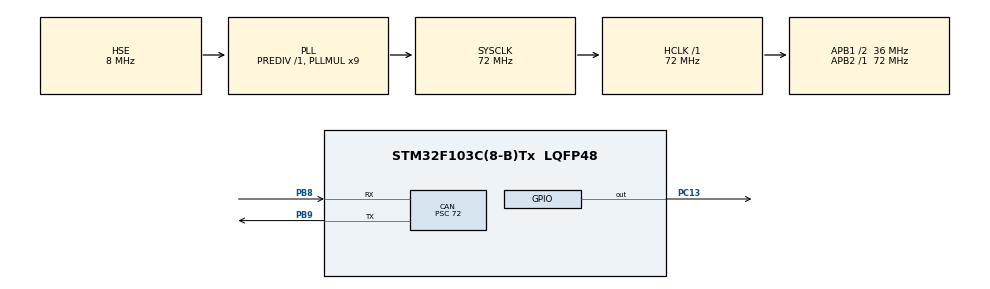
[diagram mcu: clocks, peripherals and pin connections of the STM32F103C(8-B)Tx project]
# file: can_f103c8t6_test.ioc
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CAN.ABOM=ENABLE
CAN.BS1=CAN_BS1_2TQ
CAN.CalculateBaudRate=125000
CAN.CalculateTimeBit=8000
CAN.CalculateTimeQuantum=2000.0
CAN.NART=ENABLE
CAN.Prescaler=72
Mcu.Family=STM32F1
Mcu.Name=STM32F103C(8-B)Tx
Mcu.Package=LQFP48
NVIC.CAN1_RX1_IRQn=true\:0\:0\:false\:false\:true\:true\:true\:true
NVIC.PriorityGroup=NVIC_PRIORITYGROUP_4
NVIC.TIM3_IRQn=true\:0\:0\:false\:false\:true\:true\:true\:true
PA13.Mode=Serial_Wire
PA13.Signal=SYS_JTMS-SWDIO
PA14.Mode=Serial_Wire
PA14.Signal=SYS_JTCK-SWCLK
PB8.Mode=CAN_Activate
PB8.Signal=CAN_RX
PB9.Mode=CAN_Activate
PB9.Signal=CAN_TX
PC13-TAMPER-RTC.Signal=GPIO_Output
PD0-OSC_IN.Mode=HSE-External-Oscillator
PD0-OSC_IN.Signal=RCC_OSC_IN
PD1-OSC_OUT.Mode=HSE-External-Oscillator
PD1-OSC_OUT.Signal=RCC_OSC_OUT
ProjectManager.HeapSize=0x200
ProjectManager.StackSize=0x400
ProjectManager.TargetToolchain=STM32CubeIDE
RCC.AHBFreq_Value=72000000
RCC.APB1CLKDivider=RCC_HCLK_DIV2
RCC.APB1Freq_Value=36000000
RCC.APB1TimFreq_Value=72000000
RCC.APB2Freq_Value=72000000
RCC.APB2TimFreq_Value=72000000
RCC.HCLKFreq_Value=72000000
RCC.PLLMUL=RCC_PLL_MUL9
RCC.PLLSourceVirtual=RCC_PLLSOURCE_HSE
RCC.SYSCLKFreq_VALUE=72000000
RCC.SYSCLKSource=RCC_SYSCLKSOURCE_PLLCLK
RCC.USBFreq_Value=72000000
TIM3.Period=1000-1
TIM3.Prescaler=72-1
VP_TIM3_VS_ClockSourceINT.Mode=Internal
board=custom

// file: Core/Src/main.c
/* USER CODE BEGIN Header */
/**
  ******************************************************************************
  * @file           : main.c
  * @brief          : Main program body
  ******************************************************************************
  * @attention
  *
  * Copyright (c) 2026 STMicroelectronics.
  * All rights reserved.
  *
  * This software is licensed under terms that can be found in the LICENSE file
  * in the root directory of this software component.
  * If no LICENSE file comes with this software, it is provided AS-IS.
  *
  ******************************************************************************
  */
/* USER CODE END Header */
#include "main.h"

/* USER CODE BEGIN Includes */

//--- Reference : https://www.youtube.com/watch?v=xGF5onNLZJs

//////////////////////////////////////////////////////////////////////
// PICK ONE OPTION (UNCOMMENT)
//////////////////////////////////////////////////////////////////////
//#define CAN_RX
#define CAN_TX

/* USER CODE END Includes */

CAN_HandleTypeDef hcan;

TIM_HandleTypeDef htim3;

void SystemClock_Config(void);
static void MX_GPIO_Init(void);
static void MX_CAN_Init(void);
static void MX_TIM3_Init(void);

/* USER CODE BEGIN 0 */
#ifdef CAN_TX
uint16_t readValue;
CAN_TxHeaderTypeDef TxHeader;
uint32_t TxMailbox;
uint8_t TxData[8]="HELLO---";
uint16_t txCNT = 0;
#endif

#ifdef CAN_RX
CAN_FilterTypeDef sFilterConfig;
CAN_RxHeaderTypeDef RxHeader;
uint8_t RxData[8];
uint8_t delayLED;
uint16_t delayCNT = 0;
uint8_t led_state = 0;

void HAL_CAN_RxFifo1MsgPendingCallback(CAN_HandleTypeDef *hcan)
{
	HAL_CAN_GetRxMessage(hcan, CAN_RX_FIFO1, &RxHeader, RxData);
	delayLED = RxData[7];
}
#endif

void HAL_TIM_PeriodElapsedCallback(TIM_HandleTypeDef *htim)
{
	if(htim == &htim3)
	{

#ifdef CAN_TX
		if(txCNT >= 99)
		{
			TxData[6] += 1;
			TxData[7] = TxData[6] + 1;
			txCNT = 0;
		}
		else
		{
			txCNT++;
		}

		if(HAL_CAN_GetTxMailboxesFreeLevel(&hcan) > 0)
		{
			HAL_CAN_AddTxMessage(&hcan, &TxHeader, TxData, &TxMailbox);
		}
#endif

#ifdef CAN_RX
		if(delayCNT >= delayLED)
		{
			led_state = !(led_state);
			HAL_GPIO_WritePin(GPIOC, GPIO_PIN_13, led_state);
			delayCNT = 0;
		}
		else
		{
			delayCNT++;
		}
#endif
	}
}

/* USER CODE END 0 */

int main(void)
{

  /* MCU Configuration--------------------------------------------------------*/

  /* Reset of all peripherals, Initializes the Flash interface and the Systick. */
  HAL_Init();

  /* Configure the system clock */
  SystemClock_Config();

  /* Initialize all configured peripherals */
  MX_GPIO_Init();
  MX_CAN_Init();
  MX_TIM3_Init();
  /* USER CODE BEGIN 2 */
#ifdef CAN_TX
  HAL_CAN_Start(&hcan);
  TxHeader.DLC = 8;  // data length
  TxHeader.IDE = CAN_ID_STD;
  TxHeader.RTR = CAN_RTR_DATA;
  TxHeader.StdId = 0x6A5;  // ID can be between Hex1 and Hex7FF (1-2047 decimal)
#endif

#ifdef CAN_RX
  HAL_CAN_Start(&hcan);
  // Configure the filter
  sFilterConfig.FilterActivation = CAN_FILTER_ENABLE;
  sFilterConfig.FilterFIFOAssignment = CAN_FILTER_FIFO1;
  sFilterConfig.FilterMode = CAN_FILTERMODE_IDMASK;
  sFilterConfig.FilterIdHigh = 0x6A5<<5;
  sFilterConfig.FilterIdLow = 0;
  sFilterConfig.FilterMaskIdHigh = 0x7FF<<5; // SET 0 to unfilter
  sFilterConfig.FilterMaskIdLow = 0;
  sFilterConfig.FilterScale = CAN_FILTERSCALE_32BIT;
  HAL_CAN_ConfigFilter(&hcan, &sFilterConfig);
  // Activate the notification
  HAL_CAN_ActivateNotification(&hcan, CAN_IT_RX_FIFO1_MSG_PENDING);
#endif

  HAL_TIM_Base_Start_IT(&htim3);

  /* USER CODE END 2 */

  /* Infinite loop */
  while (1)
  {

  }
}

void SystemClock_Config(void)
{
  RCC_OscInitTypeDef RCC_OscInitStruct = {0};
  RCC_ClkInitTypeDef RCC_ClkInitStruct = {0};

  /** Initializes the RCC Oscillators according to the specified parameters
  * in the RCC_OscInitTypeDef structure.
  */
  RCC_OscInitStruct.OscillatorType = RCC_OSCILLATORTYPE_HSE;
  RCC_OscInitStruct.HSEState = RCC_HSE_ON;
  RCC_OscInitStruct.HSEPredivValue = RCC_HSE_PREDIV_DIV1;
  RCC_OscInitStruct.HSIState = RCC_HSI_ON;
  RCC_OscInitStruct.PLL.PLLState = RCC_PLL_ON;
  RCC_OscInitStruct.PLL.PLLSource = RCC_PLLSOURCE_HSE;
  RCC_OscInitStruct.PLL.PLLMUL = RCC_PLL_MUL9;
  if (HAL_RCC_OscConfig(&RCC_OscInitStruct) != HAL_OK)
  {
    Error_Handler();
  }

  /** Initializes the CPU, AHB and APB buses clocks
  */
  RCC_ClkInitStruct.ClockType = RCC_CLOCKTYPE_HCLK|RCC_CLOCKTYPE_SYSCLK
                              |RCC_CLOCKTYPE_PCLK1|RCC_CLOCKTYPE_PCLK2;
  RCC_ClkInitStruct.SYSCLKSource = RCC_SYSCLKSOURCE_PLLCLK;
  RCC_ClkInitStruct.AHBCLKDivider = RCC_SYSCLK_DIV1;
  RCC_ClkInitStruct.APB1CLKDivider = RCC_HCLK_DIV2;
  RCC_ClkInitStruct.APB2CLKDivider = RCC_HCLK_DIV1;

  if (HAL_RCC_ClockConfig(&RCC_ClkInitStruct, FLASH_LATENCY_2) != HAL_OK)
  {
    Error_Handler();
  }
}

static void MX_CAN_Init(void)
{

  hcan.Instance = CAN1;
  hcan.Init.Prescaler = 72;
  hcan.Init.Mode = CAN_MODE_NORMAL;
  hcan.Init.SyncJumpWidth = CAN_SJW_1TQ;
  hcan.Init.TimeSeg1 = CAN_BS1_2TQ;
  hcan.Init.TimeSeg2 = CAN_BS2_1TQ;
  hcan.Init.TimeTriggeredMode = DISABLE;
  hcan.Init.AutoBusOff = ENABLE;
  hcan.Init.AutoWakeUp = DISABLE;
  hcan.Init.AutoRetransmission = ENABLE;
  hcan.Init.ReceiveFifoLocked = DISABLE;
  hcan.Init.TransmitFifoPriority = DISABLE;
  if (HAL_CAN_Init(&hcan) != HAL_OK)
  {
    Error_Handler();
  }

}

static void MX_TIM3_Init(void)
{

  TIM_ClockConfigTypeDef sClockSourceConfig = {0};
  TIM_MasterConfigTypeDef sMasterConfig = {0};

  htim3.Instance = TIM3;
  htim3.Init.Prescaler = 72-1;
  htim3.Init.CounterMode = TIM_COUNTERMODE_UP;
  htim3.Init.Period = 1000-1;
  htim3.Init.ClockDivision = TIM_CLOCKDIVISION_DIV1;
  htim3.Init.AutoReloadPreload = TIM_AUTORELOAD_PRELOAD_DISABLE;
  if (HAL_TIM_Base_Init(&htim3) != HAL_OK)
  {
    Error_Handler();
  }
  sClockSourceConfig.ClockSource = TIM_CLOCKSOURCE_INTERNAL;
  if (HAL_TIM_ConfigClockSource(&htim3, &sClockSourceConfig) != HAL_OK)
  {
    Error_Handler();
  }
  sMasterConfig.MasterOutputTrigger = TIM_TRGO_RESET;
  sMasterConfig.MasterSlaveMode = TIM_MASTERSLAVEMODE_DISABLE;
  if (HAL_TIMEx_MasterConfigSynchronization(&htim3, &sMasterConfig) != HAL_OK)
  {
    Error_Handler();
  }

}

static void MX_GPIO_Init(void)
{
  GPIO_InitTypeDef GPIO_InitStruct = {0};

  /* GPIO Ports Clock Enable */
  __HAL_RCC_GPIOC_CLK_ENABLE();
  __HAL_RCC_GPIOD_CLK_ENABLE();
  __HAL_RCC_GPIOA_CLK_ENABLE();
  __HAL_RCC_GPIOB_CLK_ENABLE();

  /*Configure GPIO pin Output Level */
  HAL_GPIO_WritePin(GPIOC, GPIO_PIN_13, GPIO_PIN_RESET);

  /*Configure GPIO pin : PC13 */
  GPIO_InitStruct.Pin = GPIO_PIN_13;
  GPIO_InitStruct.Mode = GPIO_MODE_OUTPUT_PP;
  GPIO_InitStruct.Pull = GPIO_NOPULL;
  GPIO_InitStruct.Speed = GPIO_SPEED_FREQ_LOW;
  HAL_GPIO_Init(GPIOC, &GPIO_InitStruct);

}

void Error_Handler(void)
{
  __disable_irq();
  while (1)
  {
  }
}
